# MKW01Z4 register map
Vendor: Freescale Semiconductor, Inc.; File version: 1.6
CPU: CM0PLUS r0p0, little endian, no MPU, no FPU, 0x2 interrupt priority bits, 0x0 interrupts
Registers are 32-bit, read-write, reset 0x0 unless marked. A register's access mark holds for its fields unless they carry their own. Offsets are from the block's base; [hi:lo] are bit positions; {n}, {i} and the like mark numbered series; 'fields as' and 'values as' point back to an identical list.

## GPIOA — General Purpose Input/Output
Base 0x400FF000; register names take the prefix GPIOA_
0x00 PDOR — Port Data Output Register
  [31:0] PDO — Port Data Output
    0=Logic level 0 is driven on pin, provided pin is configured for general-purpose output; 1=Logic level 1 is driven on pin, provided pin is configured for general-purpose output
0x04 PSOR wo — Port Set Output Register
  [31:0] PTSO — Port Set Output
    0=Corresponding bit in PDORn does not change; 1=Corresponding bit in PDORn is set to logic 1
0x08 PCOR wo — Port Clear Output Register
  [31:0] PTCO — Port Clear Output
    0=Corresponding bit in PDORn does not change; 1=Corresponding bit in PDORn is cleared to logic 0
0x0C PTOR wo — Port Toggle Output Register
  [31:0] PTTO — Port Toggle Output
    0=Corresponding bit in PDORn does not change; 1=Corresponding bit in PDORn is set to the inverse of its existing logic state
0x10 PDIR ro — Port Data Input Register
  [31:0] PDI — Port Data Input
    0=Pin logic level is logic 0, or is not configured for use by digital function; 1=Pin logic level is logic 1
0x14 PDDR — Port Data Direction Register
  [31:0] PDD — Port Data Direction
    0=Pin is configured as general-purpose input, for the GPIO function; 1=Pin is configured as general-purpose output, for the GPIO function

## GPIOB — General Purpose Input/Output
Base 0x400FF040; register names take the prefix GPIOB_
Registers as GPIOA.

## GPIOC — General Purpose Input/Output
Base 0x400FF080; register names take the prefix GPIOC_
Registers as GPIOA.

## GPIOD — General Purpose Input/Output
Base 0x400FF0C0; register names take the prefix GPIOD_
Registers as GPIOA.

## GPIOE — General Purpose Input/Output
Base 0x400FF100; register names take the prefix GPIOE_
Registers as GPIOA.

## FGPIOA — General Purpose Input/Output
Base 0xF8000000; register names take the prefix FGPIOA_
Registers as GPIOA.

## FGPIOB — General Purpose Input/Output
Base 0xF8000040; register names take the prefix FGPIOB_
Registers as GPIOA.

## FGPIOC — General Purpose Input/Output
Base 0xF8000080; register names take the prefix FGPIOC_
Registers as GPIOA.

## FGPIOD — General Purpose Input/Output
Base 0xF80000C0; register names take the prefix FGPIOD_
Registers as GPIOA.

## FGPIOE — General Purpose Input/Output
Base 0xF8000100; register names take the prefix FGPIOE_
Registers as GPIOA.

## MTB — Micro Trace Buffer
Base 0xF0000000; register names take the prefix MTB_
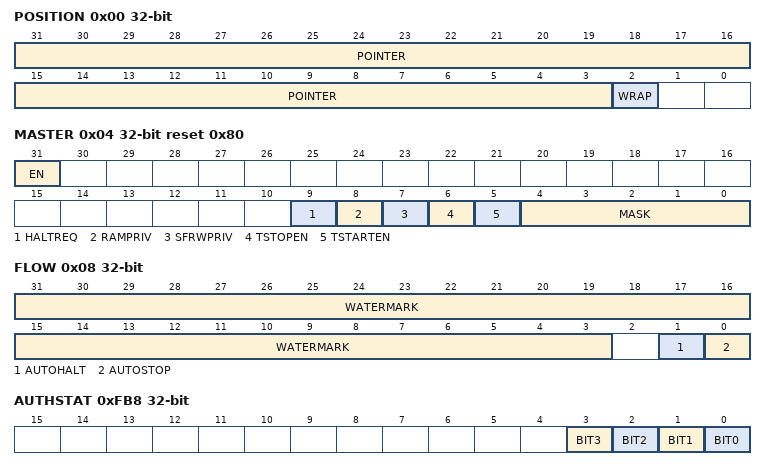
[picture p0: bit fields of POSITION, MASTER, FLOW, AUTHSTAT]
0x00 POSITION (reset mask 0x3) — MTB Position Register
  [31:3] POINTER — Trace Packet Address Pointer[28:0]
  [2] WRAP — This field is set to 1 automatically when the POINTER value wraps as determined by the MTB_MASTER[MASK] field in the MASTER Trace Control Register
0x04 MASTER reset 0x80 (reset mask 0xFFFFFFE0) — MTB Master Register
  [31] EN — Main Trace Enable
  [9] HALTREQ — Halt Request
  [8] RAMPRIV — RAM Privilege
  [7] SFRWPRIV — Special Function Register Write Privilege
  [6] TSTOPEN — Trace Stop Input Enable
  [5] TSTARTEN — Trace Start Input Enable
  [4:0] MASK
0x08 FLOW (reset mask 0x4) — MTB Flow Register
  [31:3] WATERMARK — WATERMARK[28:0]
  [1] AUTOHALT — If this field is 1 and WATERMARK is equal to MTB_POSITION[POINTER], then MTB_MASTER[HALTREQ] is automatically set to 1
  [0] AUTOSTOP — If this field is 1 and WATERMARK is equal to MTB_POSITION[POINTER], then MTB_MASTER[EN] is automatically set to 0
0x0C BASE ro reset not defined — MTB Base Register
  [31:0] BASEADDR — This value is defined with a hardwired signal and the expression: 0x2000_0000 - (RAM_Size/4)
0xF00 MODECTRL ro — Integration Mode Control Register
  [31:0] MODECTRL — Hardwired to 0x0000_0000
0xFA0 TAGSET ro — Claim TAG Set Register
  [31:0] TAGSET — Hardwired to 0x0000_0000
0xFA4 TAGCLEAR ro — Claim TAG Clear Register
  [31:0] TAGCLEAR — Hardwired to 0x0000_0000
0xFB0 LOCKACCESS ro
  [31:0] LOCKACCESS — Hardwired to 0x0000_0000
0xFB4 LOCKSTAT ro — Lock Status Register
  [31:0] LOCKSTAT — Hardwired to 0x0000_0000
0xFB8 AUTHSTAT ro — Authentication Status Register
  [3] BIT3 — Hardwired to 1.
  [2] BIT2 — Connected to NIDEN or DBGEN signal.
  [1] BIT1 — Hardwired to 1.
  [0] BIT0 — Connected to DBGEN.
0xFBC DEVICEARCH ro reset 0x47700A31 — Device Architecture Register
  [31:0] DEVICEARCH — Hardwired to 0x4770_0A31.
0xFC8 DEVICECFG ro — Device Configuration Register
  [31:0] DEVICECFG — Hardwired to 0x0000_0000.
0xFCC DEVICETYPID ro reset 0x31 — Device Type Identifier Register
  [31:0] DEVICETYPID — Hardwired to 0x0000_0031.
{0xFC0+4i} PERIPHID{i} ro reset not defined (i=4..7) — Peripheral ID Register
  [31:0] PERIPHID — Peripheral ID4 is hardwired to 0x0000_0004; ID0 to 0x0000_0032; ID1 to 0x0000_00B9; ID2 to 0x0000_000B; and all the others to 0x0000_0000
{0xFE0+4i} PERIPHID{i} ro reset not defined (i=0..3) — Peripheral ID Register
  fields as PERIPHID4
{0xFF0+4i} COMPID{i} ro reset not defined (i=0..3) — Component ID Register
  [31:0] COMPID — Component ID
